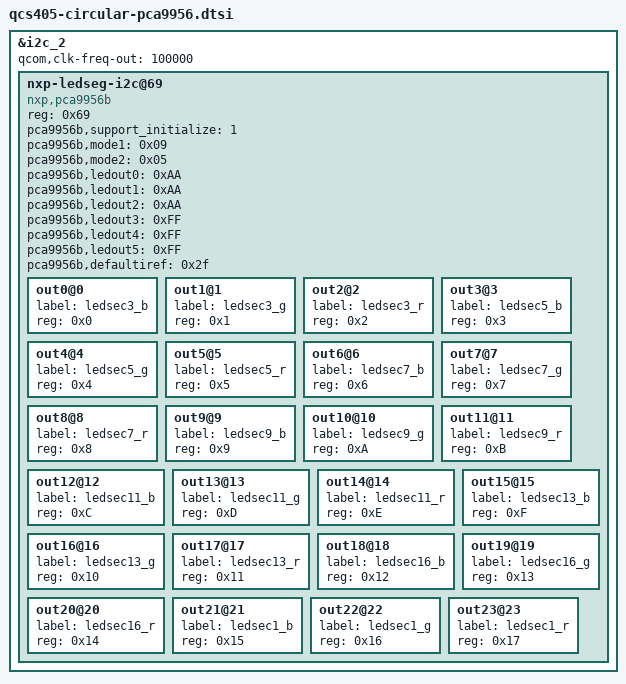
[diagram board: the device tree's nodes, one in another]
/*
 * Copyright (c) 2018, The Linux Foundation. All rights reserved.
 *
 * This program is free software; you can redistribute it and/or modify
 * it under the terms of the GNU General Public License version 2 and
 * only version 2 as published by the Free Software Foundation.
 *
 * This program is distributed in the hope that it will be useful,
 * but WITHOUT ANY WARRANTY; without even the implied warranty of
 * MERCHANTABILITY or FITNESS FOR A PARTICULAR PURPOSE.  See the
 * GNU General Public License for more details.
 */

/* Customized for DVT-1 Bahasa Kita */

&i2c_2 {
	status = "ok";
	qcom,clk-freq-out = <100000>;

	/* PCA9956B LED Drivers */
	nxp-ledseg-i2c@69 {
		#address-cells = <1>;
		#size-cells = <0>;
		compatible = "nxp,pca9956b";
		reg = <0x69>;
		pca9956b,support_initialize = <1>;
		pca9956b,mode1 = <0x09>;
		pca9956b,mode2 = <0x05>;

		pca9956b,ledout0 = <0xAA>;
		pca9956b,ledout1 = <0xAA>;
		pca9956b,ledout2 = <0xAA>;
		pca9956b,ledout3 = <0xFF>;
		pca9956b,ledout4 = <0xFF>;
		pca9956b,ledout5 = <0xFF>;
		pca9956b,defaultiref = <0x2f>;
		out0@0 {
			label = "ledsec3_b";
			reg = <0x0>;
		};
		out1@1 {
			label = "ledsec3_g";
			reg = <0x1>;
		};
		out2@2 {
			label = "ledsec3_r";
			reg = <0x2>;
		};
		out3@3 {
			label = "ledsec5_b";
			reg = <0x3>;
		};
		out4@4 {
			label = "ledsec5_g";
			reg = <0x4>;
		};
		out5@5 {
			label = "ledsec5_r";
			reg = <0x5>;
		};
		out6@6 {
			label = "ledsec7_b";
			reg = <0x6>;
		};
		out7@7 {
			label = "ledsec7_g";
			reg = <0x7>;
		};
		out8@8 {
			label = "ledsec7_r";
			reg = <0x8>;
		};
		out9@9 {
			label = "ledsec9_b";
			reg = <0x9>;
		};
		out10@10 {
			label = "ledsec9_g";
			reg = <0xA>;
		};
		out11@11 {
			label = "ledsec9_r";
			reg = <0xB>;
		};
		out12@12 {
			label = "ledsec11_b";
			reg = <0xC>;
		};
		out13@13 {
			label = "ledsec11_g";
			reg = <0xD>;
		};
		out14@14 {
			label = "ledsec11_r";
			reg = <0xE>;
		};
		out15@15 {
			label = "ledsec13_b";
			reg = <0xF>;
		};
		out16@16 {
			label = "ledsec13_g";
			reg = <0x10>;
		};
		out17@17 {
			label = "ledsec13_r";
			reg = <0x11>;
		};
		out18@18 {
			label = "ledsec16_b";
			reg = <0x12>;
		};
		out19@19 {
			label = "ledsec16_g";
			reg = <0x13>;
		};
		out20@20 {
			label = "ledsec16_r";
			reg = <0x14>;
		};
		out21@21 {
			label = "ledsec1_b";
			reg = <0x15>;
		};
		out22@22 {
			label = "ledsec1_g";
			reg = <0x16>;
		};
		out23@23 {
			label = "ledsec1_r";
			reg = <0x17>;
		};
	};
};
